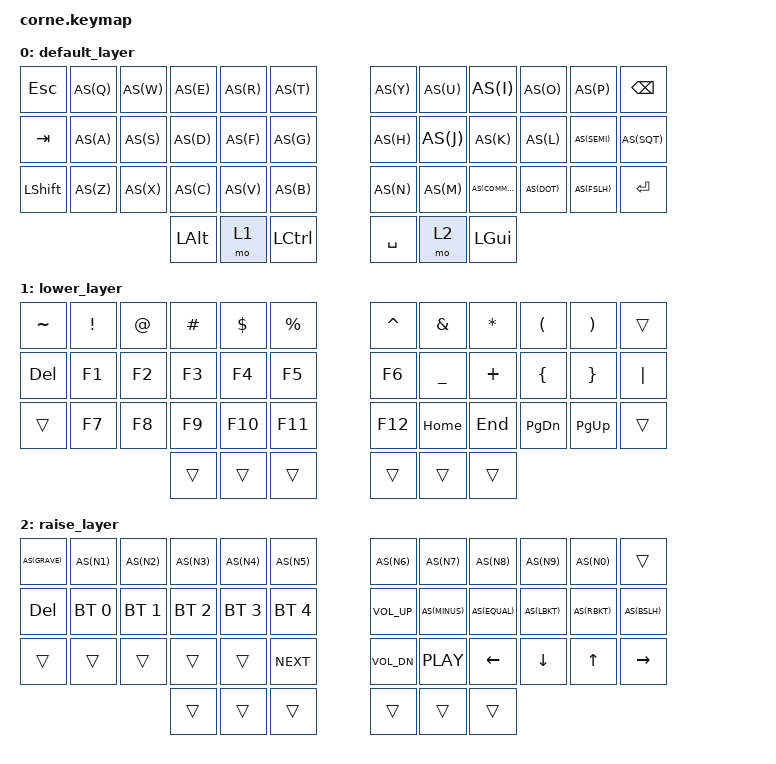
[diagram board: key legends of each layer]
/*
 * Copyright (c) 2020 The ZMK Contributors
 *
 * SPDX-License-Identifier: MIT
 */

#include <behaviors.dtsi>
#include <dt-bindings/zmk/keys.h>
#include <dt-bindings/zmk/bt.h>

#define AS(keycode) &as LS(keycode) keycode

/ {
    behaviors {
        as: auto_shift {
            compatible = "zmk,behavior-hold-tap";
            #binding-cells = <2>;
            tapping-term-ms = <200>;
            quick-tap-ms = <0>;
            flavor = "tap-preferred";
            bindings = <&kp>, <&kp>;
        };
    };

    keymap {
        compatible = "zmk,keymap";
        default_layer {
            bindings = <
   &kp ESC   AS(Q) AS(W) AS(E)    AS(R) AS(T)            AS(Y)     AS(U) AS(I)     AS(O)   AS(P)    &kp BSPC
   &kp TAB   AS(A) AS(S) AS(D)    AS(F) AS(G)            AS(H)     AS(J) AS(K)     AS(L)   AS(SEMI) AS(SQT)
   &kp LSHFT AS(Z) AS(X) AS(C)    AS(V) AS(B)            AS(N)     AS(M) AS(COMMA) AS(DOT) AS(FSLH) &kp RET
                         &kp LALT &mo 1 &kp LCTRL        &kp SPACE &mo 2 &kp LGUI
            >;
        };
        lower_layer {
            bindings = <
   &kp TILDE &kp EXCL &kp AT &kp HASH &kp DLLR &kp PRCNT        &kp CARET &kp AMPS  &kp ASTRK &kp LPAR  &kp RPAR  &trans
   &kp DEL   &kp F1   &kp F2 &kp F3   &kp F4   &kp F5           &kp F6    &kp UNDER &kp PLUS  &kp LBRC  &kp RBRC  &kp PIPE
   &trans    &kp F7   &kp F8 &kp F9   &kp F10  &kp F11          &kp F12   &kp HOME  &kp END   &kp PG_DN &kp PG_UP &trans
                             &trans   &trans   &trans           &trans    &trans    &trans
            >;
        };
        raise_layer {
            bindings = <
   AS(GRAVE) AS(N1)       AS(N2)       AS(N3)       AS(N4)       AS(N5)             AS(N6)       AS(N7)     AS(N8)    AS(N9)    AS(N0)   &trans
   &kp DEL   &bt BT_SEL 0 &bt BT_SEL 1 &bt BT_SEL 2 &bt BT_SEL 3 &bt BT_SEL 4       &kp C_VOL_UP AS(MINUS)  AS(EQUAL) AS(LBKT)  AS(RBKT) AS(BSLH)
   &trans    &trans       &trans       &trans       &trans       &kp C_NEXT         &kp C_VOL_DN &kp C_PLAY &kp LEFT  &kp DOWN  &kp UP   &kp RIGHT
                                       &trans       &trans       &trans             &trans       &trans     &trans
            >;
        };
    };
};
